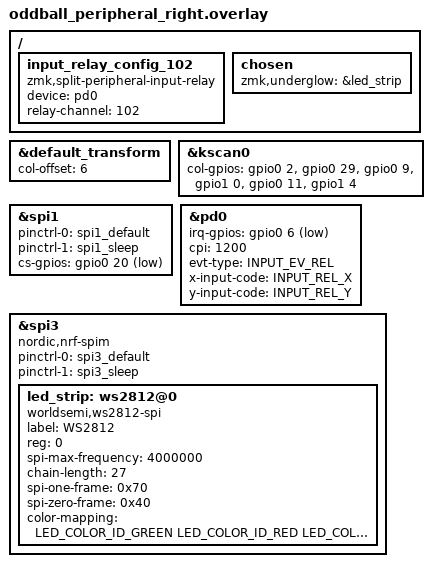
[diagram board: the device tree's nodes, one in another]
/*
 * Copyright (c) 2020 ZMK Contributors
 *
 * SPDX-License-Identifier: MIT
 */
#include <dt-bindings/led/led.h>
 
#include "oddball.dtsi"
#define INPUT_EV_KEY 0x01               /**< Key event */
#define INPUT_EV_REL 0x02               /**< Relative coordinate event */
#define INPUT_EV_ABS 0x03               /**< Absolute coordinate event */
#define INPUT_EV_MSC 0x04               /**< Miscellaneous event */
#define INPUT_EV_VENDOR_START 0xf0      /**< Vendor specific event start */
#define INPUT_EV_VENDOR_STOP 0xff       /**< Vendor specific event stop */

#define INPUT_REL_X 0x00                /**< Relative X coordinate */
#define INPUT_REL_Y 0x01                /**< Relative Y coordinate */
#define INPUT_REL_WHEEL 0x08            /**< Relative wheel coordinate */
#define INPUT_REL_HWHEEL 0x06           /**< Relative horizontal wheel coordinate */
#define INPUT_REL_MISC 0x09             /**< Relative misc coordinate */

&default_transform {
	col-offset = <6>;
};

&kscan0 {
	col-gpios
		= <&gpio0 2 (GPIO_ACTIVE_HIGH | GPIO_PULL_DOWN)>
		, <&gpio0 29 (GPIO_ACTIVE_HIGH | GPIO_PULL_DOWN)>
		, <&gpio0 9 (GPIO_ACTIVE_HIGH | GPIO_PULL_DOWN)>
		, <&gpio1 0  (GPIO_ACTIVE_HIGH | GPIO_PULL_DOWN)>
		, <&gpio0 11 (GPIO_ACTIVE_HIGH | GPIO_PULL_DOWN)>
		, <&gpio1 4  (GPIO_ACTIVE_HIGH | GPIO_PULL_DOWN)>
		;
};

#include "oddball_trackball.dtsi"

/* enable &pd0 on split peripheral. typical input device for zephyr input subsystem. */
/* NOTE 1: use the same device alias (&pd0) on central and peripheral(s) is alright. */
/* NOTE 2: input event shall be intecepted by module `zmk-split-peripheral-input-relay`. */
&spi1 {
  status = "okay";
	pinctrl-0 = <&spi1_default>;
	pinctrl-1 = <&spi1_sleep>;
	pinctrl-names = "default", "sleep";
	cs-gpios = <&gpio0 20 GPIO_ACTIVE_LOW>;
};

&pd0 {
  status = "okay";
	irq-gpios = <&gpio0 6 (GPIO_ACTIVE_LOW | GPIO_PULL_UP)>;
	cpi = <1200>;
	evt-type = <INPUT_EV_REL>;
	x-input-code = <INPUT_REL_X>;
	y-input-code = <INPUT_REL_Y>;
};

/ {
	/* for peripheral side, define (input-device)-to-(relay-channel) mapping */
	input_relay_config_102 {
		compatible = "zmk,split-peripheral-input-relay";

		/* peripheral side input device, used to be intecepted and be resurrected on central */
		device = <&pd0>;
		
		/* channel id, used to annotate raw input event */
		/* NOTE: should matching relay-channel on central overlay */
		relay-channel = <102>;
	};
};
&spi3 {
	compatible = "nordic,nrf-spim";
	status = "okay";

	pinctrl-0 = <&spi3_default>;
	pinctrl-1 = <&spi3_sleep>;
	pinctrl-names = "default", "sleep";


	led_strip: ws2812@0 {
		compatible = "worldsemi,ws2812-spi";
		label = "WS2812";

		/* SPI */
		reg = <0>; /* ignored, but necessary for SPI bindings */
		spi-max-frequency = <4000000>;

		/* WS2812 */
		chain-length = <27>; /* There are per-key RGB, but the first 6 are underglow */
		spi-one-frame = <0x70>;
		spi-zero-frame = <0x40>;
		color-mapping = <LED_COLOR_ID_GREEN LED_COLOR_ID_RED LED_COLOR_ID_BLUE>;
	};
};

/ {
	chosen {
		zmk,underglow = &led_strip;
	};
};
